# MIMXRT1021 register map
Vendor: nxp.com; File version: 1.0
CPU: CM7 r0p1, little endian, MPU, FPU, VTOR, 4 interrupt priority bits
Registers are 32-bit, read-write, reset 0x0 unless marked. A register's access mark holds for its fields unless they carry their own. Offsets are from the block's base; [hi:lo] are bit positions; {n}, {i} and the like mark numbered series; 'fields as' and 'values as' point back to an identical list.

## IOMUXC (part 3 of 3)
Base 0x401F8000; register names take the prefix IOMUXC_
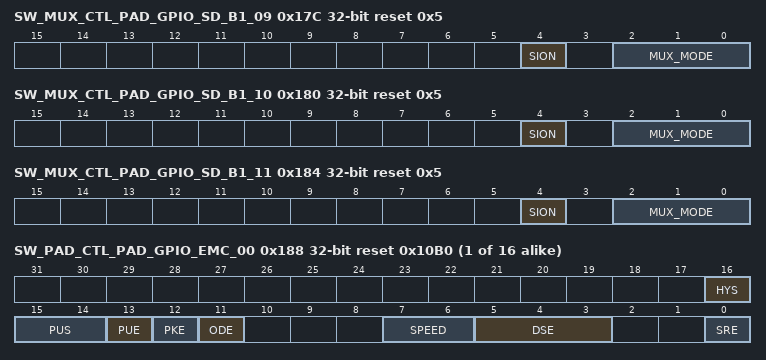
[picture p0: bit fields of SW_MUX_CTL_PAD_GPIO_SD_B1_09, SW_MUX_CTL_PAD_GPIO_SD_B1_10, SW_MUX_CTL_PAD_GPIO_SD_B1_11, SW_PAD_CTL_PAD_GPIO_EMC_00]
0x17C SW_MUX_CTL_PAD_GPIO_SD_B1_09 reset 0x5 — SW_MUX_CTL_PAD_GPIO_SD_B1_09 SW MUX Control Register
  [4] SION — Software Input On Field.
    0=DISABLED (Input Path is determined by functionality); 1=ENABLED (Force input path of pad GPIO_SD_B1_09)
  [2:0] MUX_MODE — MUX Mode Select Field.
    0=ALT0 (Select mux mode: ALT0 mux port: USDHC2_DATA5 of instance: usdhc2); 1=ALT1 (Select mux mode: ALT1 mux port: FLEXSPI_A_DATA02 of instance: flexspi_bus2bit); 2=ALT2 (Select mux mode: ALT2 mux port: ENET_TX_EN of instance: enet); 3=ALT3 (Select mux mode: ALT3 mux port: SAI3_RX_BCLK of instance: sai3); 4=ALT4 (Select mux mode: ALT4 mux port: LPSPI2_SDI of instance: lpspi2); 5=ALT5 (Select mux mode: ALT5 mux port: GPIO3_IO29 of instance: gpio3)
0x180 SW_MUX_CTL_PAD_GPIO_SD_B1_10 reset 0x5 — SW_MUX_CTL_PAD_GPIO_SD_B1_10 SW MUX Control Register
  [4] SION — Software Input On Field.
    0=DISABLED (Input Path is determined by functionality); 1=ENABLED (Force input path of pad GPIO_SD_B1_10)
  [2:0] MUX_MODE — MUX Mode Select Field.
    0=ALT0 (Select mux mode: ALT0 mux port: USDHC2_DATA6 of instance: usdhc2); 1=ALT1 (Select mux mode: ALT1 mux port: FLEXSPI_A_DATA01 of instance: flexspi_bus2bit); 2=ALT2 (Select mux mode: ALT2 mux port: ENET_TDATA00 of instance: enet); 3=ALT3 (Select mux mode: ALT3 mux port: SAI3_RX_SYNC of instance: sai3); 4=ALT4 (Select mux mode: ALT4 mux port: LPSPI2_PCS2 of instance: lpspi2); 5=ALT5 (Select mux mode: ALT5 mux port: GPIO3_IO30 of instance: gpio3)
0x184 SW_MUX_CTL_PAD_GPIO_SD_B1_11 reset 0x5 — SW_MUX_CTL_PAD_GPIO_SD_B1_11 SW MUX Control Register
  [4] SION — Software Input On Field.
    0=DISABLED (Input Path is determined by functionality); 1=ENABLED (Force input path of pad GPIO_SD_B1_11)
  [2:0] MUX_MODE — MUX Mode Select Field.
    0=ALT0 (Select mux mode: ALT0 mux port: USDHC2_DATA7 of instance: usdhc2); 1=ALT1 (Select mux mode: ALT1 mux port: FLEXSPI_A_SS0_B of instance: flexspi_bus2bit); 2=ALT2 (Select mux mode: ALT2 mux port: ENET_TDATA01 of instance: enet); 3=ALT3 (Select mux mode: ALT3 mux port: SAI3_RX_DATA of instance: sai3); 4=ALT4 (Select mux mode: ALT4 mux port: LPSPI2_PCS3 of instance: lpspi2); 5=ALT5 (Select mux mode: ALT5 mux port: GPIO3_IO31 of instance: gpio3)
{0x188+4i} SW_PAD_CTL_PAD_GPIO_EMC_{i:02} reset 0x10B0 (i=0..15) — SW_PAD_CTL_PAD_GPIO_EMC_{i:02} SW PAD Control Register
  [16] HYS — Hyst. Enable Field
    0=HYS_0_Hysteresis_Disabled (Hysteresis Disabled); 1=HYS_1_Hysteresis_Enabled (Hysteresis Enabled)
  [15:14] PUS — Pull Up / Down Config. Field
    0=PUS_0_100K_Ohm_Pull_Down (100K Ohm Pull Down); 1=PUS_1_47K_Ohm_Pull_Up (47K Ohm Pull Up); 2=PUS_2_100K_Ohm_Pull_Up (100K Ohm Pull Up); 3=PUS_3_22K_Ohm_Pull_Up (22K Ohm Pull Up)
  [13] PUE — Pull / Keep Select Field
    0=PUE_0_Keeper (Keeper); 1=PUE_1_Pull (Pull)
  [12] PKE — Pull / Keep Enable Field
    0=PKE_0_Pull_Keeper_Disabled (Pull/Keeper Disabled); 1=PKE_1_Pull_Keeper_Enabled (Pull/Keeper Enabled)
  [11] ODE — Open Drain Enable Field
    0=ODE_0_Open_Drain_Disabled (Open Drain Disabled); 1=ODE_1_Open_Drain_Enabled (Open Drain Enabled)
  [7:6] SPEED
    0=SPEED_0_Low (50MHz); 1=SPEED_1_Medium (100MHz - 150MHz); 2=SPEED_2_Medium (100MHz - 150MHz); 3=SPEED_3_Maximum (150MHz - 200MHz)
  [5:3] DSE — Drive Strength Field
    0=DSE_0_output_driver_disabled_ (output driver disabled;); 1=DSE_1_R0_150_Ohm___3_3V__260_Ohm_1_8V (R0(150 Ohm @ 3.3V, 260 Ohm@1.8V)); {v}=DSE_{v}_R0_{v} (R0/{v}) (v=2..7)
  [0] SRE — Slew Rate Field
    0=SRE_0_Slow_Slew_Rate (Slow Slew Rate); 1=SRE_1_Fast_Slew_Rate (Fast Slew Rate)
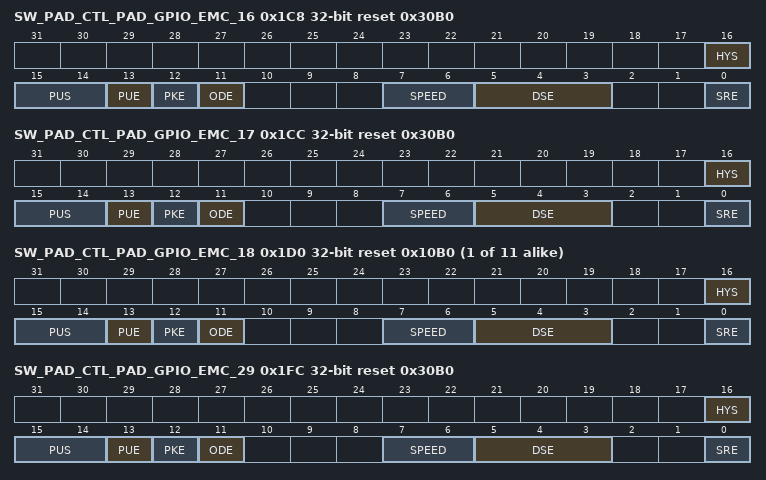
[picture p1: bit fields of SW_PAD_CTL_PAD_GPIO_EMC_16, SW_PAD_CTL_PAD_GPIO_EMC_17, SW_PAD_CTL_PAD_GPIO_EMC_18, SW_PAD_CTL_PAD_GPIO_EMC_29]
0x1C8 SW_PAD_CTL_PAD_GPIO_EMC_16 reset 0x30B0 — SW_PAD_CTL_PAD_GPIO_EMC_16 SW PAD Control Register
  fields as SW_PAD_CTL_PAD_GPIO_EMC_00
0x1CC SW_PAD_CTL_PAD_GPIO_EMC_17 reset 0x30B0 — SW_PAD_CTL_PAD_GPIO_EMC_17 SW PAD Control Register
  fields as SW_PAD_CTL_PAD_GPIO_EMC_00
{0x188+4i} SW_PAD_CTL_PAD_GPIO_EMC_{i} reset 0x10B0 (i=18..28) — SW_PAD_CTL_PAD_GPIO_EMC_{i} SW PAD Control Register
  fields as SW_PAD_CTL_PAD_GPIO_EMC_00
0x1FC SW_PAD_CTL_PAD_GPIO_EMC_29 reset 0x30B0 — SW_PAD_CTL_PAD_GPIO_EMC_29 SW PAD Control Register
  fields as SW_PAD_CTL_PAD_GPIO_EMC_00
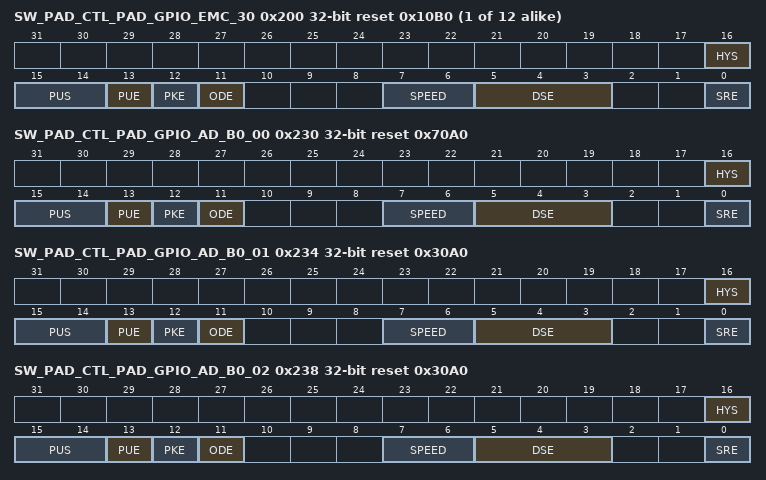
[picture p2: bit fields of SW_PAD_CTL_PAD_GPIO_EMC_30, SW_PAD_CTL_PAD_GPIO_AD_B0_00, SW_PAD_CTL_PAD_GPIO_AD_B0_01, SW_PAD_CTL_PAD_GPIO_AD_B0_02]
{0x188+4i} SW_PAD_CTL_PAD_GPIO_EMC_{i} reset 0x10B0 (i=30..41) — SW_PAD_CTL_PAD_GPIO_EMC_{i} SW PAD Control Register
  fields as SW_PAD_CTL_PAD_GPIO_EMC_00
0x230 SW_PAD_CTL_PAD_GPIO_AD_B0_00 reset 0x70A0 — SW_PAD_CTL_PAD_GPIO_AD_B0_00 SW PAD Control Register
  fields as SW_PAD_CTL_PAD_GPIO_EMC_00
0x234 SW_PAD_CTL_PAD_GPIO_AD_B0_01 reset 0x30A0 — SW_PAD_CTL_PAD_GPIO_AD_B0_01 SW PAD Control Register
  fields as SW_PAD_CTL_PAD_GPIO_EMC_00
0x238 SW_PAD_CTL_PAD_GPIO_AD_B0_02 reset 0x30A0 — SW_PAD_CTL_PAD_GPIO_AD_B0_02 SW PAD Control Register
  fields as SW_PAD_CTL_PAD_GPIO_EMC_00
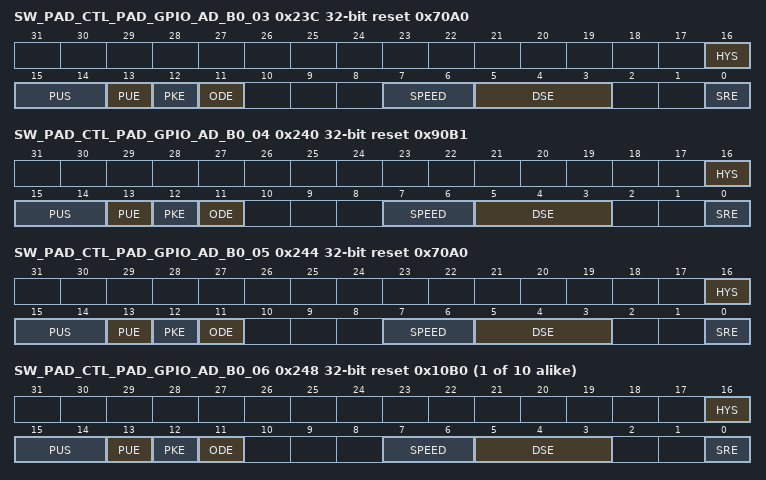
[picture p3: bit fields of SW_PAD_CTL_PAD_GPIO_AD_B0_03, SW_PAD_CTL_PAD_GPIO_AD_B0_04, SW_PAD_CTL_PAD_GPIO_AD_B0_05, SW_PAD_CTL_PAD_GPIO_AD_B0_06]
0x23C SW_PAD_CTL_PAD_GPIO_AD_B0_03 reset 0x70A0 — SW_PAD_CTL_PAD_GPIO_AD_B0_03 SW PAD Control Register
  fields as SW_PAD_CTL_PAD_GPIO_EMC_00
0x240 SW_PAD_CTL_PAD_GPIO_AD_B0_04 reset 0x90B1 — SW_PAD_CTL_PAD_GPIO_AD_B0_04 SW PAD Control Register
  fields as SW_PAD_CTL_PAD_GPIO_EMC_00
0x244 SW_PAD_CTL_PAD_GPIO_AD_B0_05 reset 0x70A0 — SW_PAD_CTL_PAD_GPIO_AD_B0_05 SW PAD Control Register
  fields as SW_PAD_CTL_PAD_GPIO_EMC_00
{0x230+4i} SW_PAD_CTL_PAD_GPIO_AD_B0_{i:02} reset 0x10B0 (i=6..15) — SW_PAD_CTL_PAD_GPIO_AD_B0_{i:02} SW PAD Control Register
  fields as SW_PAD_CTL_PAD_GPIO_EMC_00
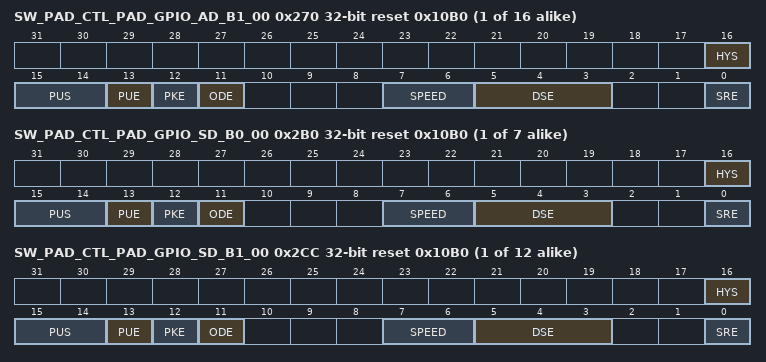
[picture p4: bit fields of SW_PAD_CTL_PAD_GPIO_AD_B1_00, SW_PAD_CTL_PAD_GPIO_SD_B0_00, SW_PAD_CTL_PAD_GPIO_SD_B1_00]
{0x270+4i} SW_PAD_CTL_PAD_GPIO_AD_B1_{i:02} reset 0x10B0 (i=0..15) — SW_PAD_CTL_PAD_GPIO_AD_B1_{i:02} SW PAD Control Register
  fields as SW_PAD_CTL_PAD_GPIO_EMC_00
{0x2B0+4i} SW_PAD_CTL_PAD_GPIO_SD_B0_{i:02} reset 0x10B0 (i=0..6) — SW_PAD_CTL_PAD_GPIO_SD_B0_{i:02} SW PAD Control Register
  fields as SW_PAD_CTL_PAD_GPIO_EMC_00
{0x2CC+4i} SW_PAD_CTL_PAD_GPIO_SD_B1_{i:02} reset 0x10B0 (i=0..11) — SW_PAD_CTL_PAD_GPIO_SD_B1_{i:02} SW PAD Control Register
  fields as SW_PAD_CTL_PAD_GPIO_EMC_00
0x2FC ANATOP_USB_OTG_ID_SELECT_INPUT — ANATOP_USB_OTG_ID_SELECT_INPUT DAISY Register
  [1:0] DAISY — Selecting Pads Involved in Daisy Chain.
    0=GPIO_AD_B0_05_ALT6 (Selecting Pad: GPIO_AD_B0_05 for Mode: ALT6); 1=GPIO_AD_B1_11_ALT0 (Selecting Pad: GPIO_AD_B1_11 for Mode: ALT0); 2=GPIO_EMC_40_ALT3 (Selecting Pad: GPIO_EMC_40 for Mode: ALT3)
0x300 CCM_PMIC_READY_SELECT_INPUT — CCM_PMIC_READY_SELECT_INPUT DAISY Register
  [1:0] DAISY — Selecting Pads Involved in Daisy Chain.
    0=GPIO_EMC_13_ALT7 (Selecting Pad: GPIO_EMC_13 for Mode: ALT7); 1=GPIO_SD_B1_05_ALT6 (Selecting Pad: GPIO_SD_B1_05 for Mode: ALT6); 2=GPIO_AD_B0_03_ALT7 (Selecting Pad: GPIO_AD_B0_03 for Mode: ALT7); 3=GPIO_EMC_36_ALT3 (Selecting Pad: GPIO_EMC_36 for Mode: ALT3)
0x304 ENET_RMII_SELECT_INPUT — ENET_RMII_SELECT_INPUT DAISY Register
  [0] DAISY — Selecting Pads Involved in Daisy Chain.
    0=GPIO_SD_B1_04_ALT3 (Selecting Pad: GPIO_SD_B1_04 for Mode: ALT3); 1=GPIO_AD_B0_08_ALT4 (Selecting Pad: GPIO_AD_B0_08 for Mode: ALT4)
0x308 ENET_MDIO_SELECT_INPUT — ENET_MDIO_SELECT_INPUT DAISY Register
  [1:0] DAISY — Selecting Pads Involved in Daisy Chain.
    0=GPIO_SD_B0_02_ALT6 (Selecting Pad: GPIO_SD_B0_02 for Mode: ALT6); 1=GPIO_AD_B0_04_ALT4 (Selecting Pad: GPIO_AD_B0_04 for Mode: ALT4); 2=GPIO_EMC_40_ALT4 (Selecting Pad: GPIO_EMC_40 for Mode: ALT4)
0x30C ENET_RX_DATA0_SELECT_INPUT — ENET_RX_DATA0_SELECT_INPUT DAISY Register
  [0] DAISY — Selecting Pads Involved in Daisy Chain.
    0=GPIO_SD_B1_06_ALT2 (Selecting Pad: GPIO_SD_B1_06 for Mode: ALT2); 1=GPIO_AD_B0_10_ALT0 (Selecting Pad: GPIO_AD_B0_10 for Mode: ALT0)
0x310 ENET_RX_DATA1_SELECT_INPUT — ENET_RX_DATA1_SELECT_INPUT DAISY Register
  [0] DAISY — Selecting Pads Involved in Daisy Chain.
    0=GPIO_SD_B1_05_ALT2 (Selecting Pad: GPIO_SD_B1_05 for Mode: ALT2); 1=GPIO_AD_B0_09_ALT0 (Selecting Pad: GPIO_AD_B0_09 for Mode: ALT0)
0x314 ENET_RX_EN_SELECT_INPUT — ENET_RX_EN_SELECT_INPUT DAISY Register
  [0] DAISY — Selecting Pads Involved in Daisy Chain.
    0=GPIO_SD_B1_07_ALT2 (Selecting Pad: GPIO_SD_B1_07 for Mode: ALT2); 1=GPIO_AD_B0_11_ALT0 (Selecting Pad: GPIO_AD_B0_11 for Mode: ALT0)
0x318 ENET_RX_ERR_SELECT_INPUT — ENET_RX_ERR_SELECT_INPUT DAISY Register
  [0] DAISY — Selecting Pads Involved in Daisy Chain.
    0=GPIO_SD_B1_08_ALT2 (Selecting Pad: GPIO_SD_B1_08 for Mode: ALT2); 1=GPIO_AD_B0_12_ALT0 (Selecting Pad: GPIO_AD_B0_12 for Mode: ALT0)
0x31C ENET_TX_CLK_SELECT_INPUT — ENET_TX_CLK_SELECT_INPUT DAISY Register
  [0] DAISY — Selecting Pads Involved in Daisy Chain.
    0=GPIO_SD_B1_04_ALT2 (Selecting Pad: GPIO_SD_B1_04 for Mode: ALT2); 1=GPIO_AD_B0_08_ALT0 (Selecting Pad: GPIO_AD_B0_08 for Mode: ALT0)
0x320 FLEXCAN1_RX_SELECT_INPUT — FLEXCAN1_RX_SELECT_INPUT DAISY Register
  [1:0] DAISY — Selecting Pads Involved in Daisy Chain.
    0=GPIO_EMC_01_ALT6 (Selecting Pad: GPIO_EMC_01 for Mode: ALT6); 1=GPIO_SD_B1_01_ALT4 (Selecting Pad: GPIO_SD_B1_01 for Mode: ALT4); 2=GPIO_AD_B0_05_ALT1 (Selecting Pad: GPIO_AD_B0_05 for Mode: ALT1); 3=GPIO_EMC_15_ALT6 (Selecting Pad: GPIO_EMC_15 for Mode: ALT6)
0x324 FLEXCAN2_RX_SELECT_INPUT — FLEXCAN2_RX_SELECT_INPUT DAISY Register
  [1:0] DAISY — Selecting Pads Involved in Daisy Chain.
    0=GPIO_SD_B0_05_ALT1 (Selecting Pad: GPIO_SD_B0_05 for Mode: ALT1); 1=GPIO_EMC_09_ALT2 (Selecting Pad: GPIO_EMC_09 for Mode: ALT2); 2=GPIO_AD_B0_15_ALT1 (Selecting Pad: GPIO_AD_B0_15 for Mode: ALT1); 3=GPIO_AD_B1_01_ALT2 (Selecting Pad: GPIO_AD_B1_01 for Mode: ALT2)
0x328 FLEXPWM1_PWMA0_SELECT_INPUT — FLEXPWM1_PWMA0_SELECT_INPUT DAISY Register
  [0] DAISY — Selecting Pads Involved in Daisy Chain.
    0=GPIO_AD_B1_06_ALT1 (Selecting Pad: GPIO_AD_B1_06 for Mode: ALT1); 1=GPIO_EMC_26_ALT1 (Selecting Pad: GPIO_EMC_26 for Mode: ALT1)
0x32C FLEXPWM1_PWMA1_SELECT_INPUT — FLEXPWM1_PWMA1_SELECT_INPUT DAISY Register
  [0] DAISY — Selecting Pads Involved in Daisy Chain.
    0=GPIO_AD_B1_08_ALT1 (Selecting Pad: GPIO_AD_B1_08 for Mode: ALT1); 1=GPIO_EMC_24_ALT1 (Selecting Pad: GPIO_EMC_24 for Mode: ALT1)
0x330 FLEXPWM1_PWMA2_SELECT_INPUT — FLEXPWM1_PWMA2_SELECT_INPUT DAISY Register
  [0] DAISY — Selecting Pads Involved in Daisy Chain.
    0=GPIO_AD_B1_10_ALT1 (Selecting Pad: GPIO_AD_B1_10 for Mode: ALT1); 1=GPIO_EMC_22_ALT1 (Selecting Pad: GPIO_EMC_22 for Mode: ALT1)
0x334 FLEXPWM1_PWMA3_SELECT_INPUT — FLEXPWM1_PWMA3_SELECT_INPUT DAISY Register
  [0] DAISY — Selecting Pads Involved in Daisy Chain.
    0=GPIO_AD_B1_12_ALT6 (Selecting Pad: GPIO_AD_B1_12 for Mode: ALT6); 1=GPIO_EMC_20_ALT1 (Selecting Pad: GPIO_EMC_20 for Mode: ALT1)
0x338 FLEXPWM1_PWMB0_SELECT_INPUT — FLEXPWM1_PWMB0_SELECT_INPUT DAISY Register
  [0] DAISY — Selecting Pads Involved in Daisy Chain.
    0=GPIO_AD_B1_07_ALT1 (Selecting Pad: GPIO_AD_B1_07 for Mode: ALT1); 1=GPIO_EMC_27_ALT1 (Selecting Pad: GPIO_EMC_27 for Mode: ALT1)
0x33C FLEXPWM1_PWMB1_SELECT_INPUT — FLEXPWM1_PWMB1_SELECT_INPUT DAISY Register
  [0] DAISY — Selecting Pads Involved in Daisy Chain.
    0=GPIO_AD_B1_09_ALT1 (Selecting Pad: GPIO_AD_B1_09 for Mode: ALT1); 1=GPIO_EMC_25_ALT1 (Selecting Pad: GPIO_EMC_25 for Mode: ALT1)
0x340 FLEXPWM1_PWMB2_SELECT_INPUT — FLEXPWM1_PWMB2_SELECT_INPUT DAISY Register
  [0] DAISY — Selecting Pads Involved in Daisy Chain.
    0=GPIO_AD_B1_11_ALT1 (Selecting Pad: GPIO_AD_B1_11 for Mode: ALT1); 1=GPIO_EMC_23_ALT1 (Selecting Pad: GPIO_EMC_23 for Mode: ALT1)
0x344 FLEXPWM1_PWMB3_SELECT_INPUT — FLEXPWM1_PWMB3_SELECT_INPUT DAISY Register
  [0] DAISY — Selecting Pads Involved in Daisy Chain.
    0=GPIO_AD_B1_13_ALT6 (Selecting Pad: GPIO_AD_B1_13 for Mode: ALT6); 1=GPIO_EMC_21_ALT1 (Selecting Pad: GPIO_EMC_21 for Mode: ALT1)
0x348 FLEXPWM2_PWMA0_SELECT_INPUT — FLEXPWM2_PWMA0_SELECT_INPUT DAISY Register
  [0] DAISY — Selecting Pads Involved in Daisy Chain.
    0=GPIO_AD_B0_14_ALT4 (Selecting Pad: GPIO_AD_B0_14 for Mode: ALT4); 1=GPIO_EMC_38_ALT1 (Selecting Pad: GPIO_EMC_38 for Mode: ALT1)
0x34C FLEXPWM2_PWMA1_SELECT_INPUT — FLEXPWM2_PWMA1_SELECT_INPUT DAISY Register
  [0] DAISY — Selecting Pads Involved in Daisy Chain.
    0=GPIO_AD_B0_12_ALT4 (Selecting Pad: GPIO_AD_B0_12 for Mode: ALT4); 1=GPIO_EMC_36_ALT1 (Selecting Pad: GPIO_EMC_36 for Mode: ALT1)
0x350 FLEXPWM2_PWMA2_SELECT_INPUT — FLEXPWM2_PWMA2_SELECT_INPUT DAISY Register
  [0] DAISY — Selecting Pads Involved in Daisy Chain.
    0=GPIO_AD_B0_10_ALT4 (Selecting Pad: GPIO_AD_B0_10 for Mode: ALT4); 1=GPIO_EMC_30_ALT1 (Selecting Pad: GPIO_EMC_30 for Mode: ALT1)
0x354 FLEXPWM2_PWMA3_SELECT_INPUT — FLEXPWM2_PWMA3_SELECT_INPUT DAISY Register
  [0] DAISY — Selecting Pads Involved in Daisy Chain.
    0=GPIO_AD_B0_06_ALT4 (Selecting Pad: GPIO_AD_B0_06 for Mode: ALT4); 1=GPIO_EMC_28_ALT1 (Selecting Pad: GPIO_EMC_28 for Mode: ALT1)
0x358 FLEXPWM2_PWMB0_SELECT_INPUT — FLEXPWM2_PWMB0_SELECT_INPUT DAISY Register
  [0] DAISY — Selecting Pads Involved in Daisy Chain.
    0=GPIO_AD_B0_15_ALT4 (Selecting Pad: GPIO_AD_B0_15 for Mode: ALT4); 1=GPIO_EMC_39_ALT1 (Selecting Pad: GPIO_EMC_39 for Mode: ALT1)
0x35C FLEXPWM2_PWMB1_SELECT_INPUT — FLEXPWM2_PWMB1_SELECT_INPUT DAISY Register
  [0] DAISY — Selecting Pads Involved in Daisy Chain.
    0=GPIO_AD_B0_13_ALT4 (Selecting Pad: GPIO_AD_B0_13 for Mode: ALT4); 1=GPIO_EMC_37_ALT1 (Selecting Pad: GPIO_EMC_37 for Mode: ALT1)
0x360 FLEXPWM2_PWMB2_SELECT_INPUT — FLEXPWM2_PWMB2_SELECT_INPUT DAISY Register
  [0] DAISY — Selecting Pads Involved in Daisy Chain.
    0=GPIO_AD_B0_11_ALT4 (Selecting Pad: GPIO_AD_B0_11 for Mode: ALT4); 1=GPIO_EMC_31_ALT1 (Selecting Pad: GPIO_EMC_31 for Mode: ALT1)
0x364 FLEXPWM2_PWMB3_SELECT_INPUT — FLEXPWM2_PWMB3_SELECT_INPUT DAISY Register
  [0] DAISY — Selecting Pads Involved in Daisy Chain.
    0=GPIO_AD_B0_07_ALT4 (Selecting Pad: GPIO_AD_B0_07 for Mode: ALT4); 1=GPIO_EMC_29_ALT1 (Selecting Pad: GPIO_EMC_29 for Mode: ALT1)
0x368 FLEXSPI_A_DATA0_SELECT_INPUT — FLEXSPI_A_DATA0_SELECT_INPUT DAISY Register
  [0] DAISY — Selecting Pads Involved in Daisy Chain.
    0=GPIO_SD_B1_08_ALT1 (Selecting Pad: GPIO_SD_B1_08 for Mode: ALT1); 1=GPIO_AD_B1_02_ALT1 (Selecting Pad: GPIO_AD_B1_02 for Mode: ALT1)
0x36C FLEXSPI_A_DATA1_SELECT_INPUT — FLEXSPI_A_DATA1_SELECT_INPUT DAISY Register
  [0] DAISY — Selecting Pads Involved in Daisy Chain.
    0=GPIO_SD_B1_10_ALT1 (Selecting Pad: GPIO_SD_B1_10 for Mode: ALT1); 1=GPIO_AD_B1_04_ALT1 (Selecting Pad: GPIO_AD_B1_04 for Mode: ALT1)
0x370 FLEXSPI_A_DATA2_SELECT_INPUT — FLEXSPI_A_DATA2_SELECT_INPUT DAISY Register
  [0] DAISY — Selecting Pads Involved in Daisy Chain.
    0=GPIO_SD_B1_09_ALT1 (Selecting Pad: GPIO_SD_B1_09 for Mode: ALT1); 1=GPIO_AD_B1_03_ALT1 (Selecting Pad: GPIO_AD_B1_03 for Mode: ALT1)
0x374 FLEXSPI_A_DATA3_SELECT_INPUT — FLEXSPI_A_DATA3_SELECT_INPUT DAISY Register
  [0] DAISY — Selecting Pads Involved in Daisy Chain.
    0=GPIO_SD_B1_06_ALT1 (Selecting Pad: GPIO_SD_B1_06 for Mode: ALT1); 1=GPIO_AD_B1_00_ALT1 (Selecting Pad: GPIO_AD_B1_00 for Mode: ALT1)
0x378 FLEXSPI_A_SCLK_SELECT_INPUT — FLEXSPI_A_SCLK_SELECT_INPUT DAISY Register
  [0] DAISY — Selecting Pads Involved in Daisy Chain.
    0=GPIO_SD_B1_07_ALT1 (Selecting Pad: GPIO_SD_B1_07 for Mode: ALT1); 1=GPIO_AD_B1_01_ALT1 (Selecting Pad: GPIO_AD_B1_01 for Mode: ALT1)
0x37C LPI2C1_SCL_SELECT_INPUT — LPI2C1_SCL_SELECT_INPUT DAISY Register
  [0] DAISY — Selecting Pads Involved in Daisy Chain.
    0=GPIO_EMC_02_ALT6 (Selecting Pad: GPIO_EMC_02 for Mode: ALT6); 1=GPIO_AD_B1_14_ALT0 (Selecting Pad: GPIO_AD_B1_14 for Mode: ALT0)
0x380 LPI2C1_SDA_SELECT_INPUT — LPI2C1_SDA_SELECT_INPUT DAISY Register
  [0] DAISY — Selecting Pads Involved in Daisy Chain.
    0=GPIO_EMC_03_ALT6 (Selecting Pad: GPIO_EMC_03 for Mode: ALT6); 1=GPIO_AD_B1_15_ALT0 (Selecting Pad: GPIO_AD_B1_15 for Mode: ALT0)
0x384 LPI2C2_SCL_SELECT_INPUT — LPI2C2_SCL_SELECT_INPUT DAISY Register
  [0] DAISY — Selecting Pads Involved in Daisy Chain.
    0=GPIO_AD_B1_08_ALT0 (Selecting Pad: GPIO_AD_B1_08 for Mode: ALT0); 1=GPIO_EMC_19_ALT2 (Selecting Pad: GPIO_EMC_19 for Mode: ALT2)
0x388 LPI2C2_SDA_SELECT_INPUT — LPI2C2_SDA_SELECT_INPUT DAISY Register
  [0] DAISY — Selecting Pads Involved in Daisy Chain.
    0=GPIO_AD_B1_09_ALT0 (Selecting Pad: GPIO_AD_B1_09 for Mode: ALT0); 1=GPIO_EMC_18_ALT2 (Selecting Pad: GPIO_EMC_18 for Mode: ALT2)
0x38C LPI2C3_SCL_SELECT_INPUT — LPI2C3_SCL_SELECT_INPUT DAISY Register
  [0] DAISY — Selecting Pads Involved in Daisy Chain.
    0=GPIO_SD_B0_00_ALT4 (Selecting Pad: GPIO_SD_B0_00 for Mode: ALT4); 1=GPIO_AD_B0_08_ALT1 (Selecting Pad: GPIO_AD_B0_08 for Mode: ALT1)
0x390 LPI2C3_SDA_SELECT_INPUT — LPI2C3_SDA_SELECT_INPUT DAISY Register
  [0] DAISY — Selecting Pads Involved in Daisy Chain.
    0=GPIO_SD_B0_01_ALT4 (Selecting Pad: GPIO_SD_B0_01 for Mode: ALT4); 1=GPIO_AD_B0_09_ALT1 (Selecting Pad: GPIO_AD_B0_09 for Mode: ALT1)
0x394 LPI2C4_SCL_SELECT_INPUT — LPI2C4_SCL_SELECT_INPUT DAISY Register
  [0] DAISY — Selecting Pads Involved in Daisy Chain.
    0=GPIO_EMC_11_ALT2 (Selecting Pad: GPIO_EMC_11 for Mode: ALT2); 1=GPIO_SD_B1_02_ALT3 (Selecting Pad: GPIO_SD_B1_02 for Mode: ALT3)
0x398 LPI2C4_SDA_SELECT_INPUT — LPI2C4_SDA_SELECT_INPUT DAISY Register
  [0] DAISY — Selecting Pads Involved in Daisy Chain.
    0=GPIO_EMC_10_ALT2 (Selecting Pad: GPIO_EMC_10 for Mode: ALT2); 1=GPIO_SD_B1_03_ALT3 (Selecting Pad: GPIO_SD_B1_03 for Mode: ALT3)
0x39C LPSPI1_PCS0_SELECT_INPUT — LPSPI1_PCS0_SELECT_INPUT DAISY Register
  [0] DAISY — Selecting Pads Involved in Daisy Chain.
    0=GPIO_SD_B0_03_ALT4 (Selecting Pad: GPIO_SD_B0_03 for Mode: ALT4); 1=GPIO_AD_B0_11_ALT1 (Selecting Pad: GPIO_AD_B0_11 for Mode: ALT1)
0x3A0 LPSPI1_SCK_SELECT_INPUT — LPSPI1_SCK_SELECT_INPUT DAISY Register
  [0] DAISY — Selecting Pads Involved in Daisy Chain.
    0=GPIO_SD_B0_02_ALT4 (Selecting Pad: GPIO_SD_B0_02 for Mode: ALT4); 1=GPIO_AD_B0_10_ALT1 (Selecting Pad: GPIO_AD_B0_10 for Mode: ALT1)
0x3A4 LPSPI1_SDI_SELECT_INPUT — LPSPI1_SDI_SELECT_INPUT DAISY Register
  [0] DAISY — Selecting Pads Involved in Daisy Chain.
    0=GPIO_SD_B0_05_ALT4 (Selecting Pad: GPIO_SD_B0_05 for Mode: ALT4); 1=GPIO_AD_B0_13_ALT1 (Selecting Pad: GPIO_AD_B0_13 for Mode: ALT1)
0x3A8 LPSPI1_SDO_SELECT_INPUT — LPSPI1_SDO_SELECT_INPUT DAISY Register
  [0] DAISY — Selecting Pads Involved in Daisy Chain.
    0=GPIO_SD_B0_04_ALT4 (Selecting Pad: GPIO_SD_B0_04 for Mode: ALT4); 1=GPIO_AD_B0_12_ALT1 (Selecting Pad: GPIO_AD_B0_12 for Mode: ALT1)
0x3AC LPSPI2_PCS0_SELECT_INPUT — LPSPI2_PCS0_SELECT_INPUT DAISY Register
  [1:0] DAISY — Selecting Pads Involved in Daisy Chain.
    0=GPIO_EMC_01_ALT4 (Selecting Pad: GPIO_EMC_01 for Mode: ALT4); 1=GPIO_EMC_11_ALT4 (Selecting Pad: GPIO_EMC_11 for Mode: ALT4); 2=GPIO_SD_B1_06_ALT4 (Selecting Pad: GPIO_SD_B1_06 for Mode: ALT4)
0x3B0 LPSPI2_SCK_SELECT_INPUT — LPSPI2_SCK_SELECT_INPUT DAISY Register
  [1:0] DAISY — Selecting Pads Involved in Daisy Chain.
    0=_GPIO_EMC_00_ALT4 (Selecting Pad: GPIO_EMC_00 for Mode: ALT4); 1=_GPIO_EMC_10_ALT4 (Selecting Pad: GPIO_EMC_10 for Mode: ALT4); 2=_GPIO_SD_B1_07_ALT4 (Selecting Pad: GPIO_SD_B1_07 for Mode: ALT4)
0x3B4 LPSPI2_SDI_SELECT_INPUT — LPSPI2_SDI_SELECT_INPUT DAISY Register
  [1:0] DAISY — Selecting Pads Involved in Daisy Chain.
    0=GPIO_EMC_03_ALT4 (Selecting Pad: GPIO_EMC_03 for Mode: ALT4); 1=GPIO_EMC_13_ALT4 (Selecting Pad: GPIO_EMC_13 for Mode: ALT4); 2=GPIO_SD_B1_09_ALT4 (Selecting Pad: GPIO_SD_B1_09 for Mode: ALT4)
0x3B8 LPSPI2_SDO_SELECT_INPUT — LPSPI2_SDO_SELECT_INPUT DAISY Register
  [1:0] DAISY — Selecting Pads Involved in Daisy Chain.
    0=GPIO_EMC_02_ALT4 (Selecting Pad: GPIO_EMC_02 for Mode: ALT4); 1=GPIO_EMC_12_ALT4 (Selecting Pad: GPIO_EMC_12 for Mode: ALT4); 2=GPIO_SD_B1_08_ALT4 (Selecting Pad: GPIO_SD_B1_08 for Mode: ALT4)
0x3BC LPSPI4_PCS0_SELECT_INPUT — LPSPI4_PCS0_SELECT_INPUT DAISY Register
  [0] DAISY — Selecting Pads Involved in Daisy Chain.
    0=GPIO_AD_B1_03_ALT2 (Selecting Pad: GPIO_AD_B1_03 for Mode: ALT2); 1=GPIO_EMC_33_ALT4 (Selecting Pad: GPIO_EMC_33 for Mode: ALT4)
0x3C0 LPSPI4_SCK_SELECT_INPUT — LPSPI4_SCK_SELECT_INPUT DAISY Register
  [0] DAISY — Selecting Pads Involved in Daisy Chain.
    0=GPIO_AD_B1_02_ALT2 (Selecting Pad: GPIO_AD_B1_02 for Mode: ALT2); 1=GPIO_EMC_32_ALT4 (Selecting Pad: GPIO_EMC_32 for Mode: ALT4)
0x3C4 LPSPI4_SDI_SELECT_INPUT — LPSPI4_SDI_SELECT_INPUT DAISY Register
  [0] DAISY — Selecting Pads Involved in Daisy Chain.
    0=GPIO_AD_B1_05_ALT2 (Selecting Pad: GPIO_AD_B1_05 for Mode: ALT2); 1=GPIO_EMC_35_ALT4 (Selecting Pad: GPIO_EMC_35 for Mode: ALT4)
0x3C8 LPSPI4_SDO_SELECT_INPUT — LPSPI4_SDO_SELECT_INPUT DAISY Register
  [0] DAISY — Selecting Pads Involved in Daisy Chain.
    0=GPIO_AD_B1_04_ALT2 (Selecting Pad: GPIO_AD_B1_04 for Mode: ALT2); 1=GPIO_EMC_34_ALT4 (Selecting Pad: GPIO_EMC_34 for Mode: ALT4)
0x3CC LPUART2_CTS_B_SELECT_INPUT — LPUART2_CTS_B_SELECT_INPUT DAISY Register
  [0] DAISY — Selecting Pads Involved in Daisy Chain.
    0=GPIO_AD_B1_06_ALT2 (Selecting Pad: GPIO_AD_B1_06 for Mode: ALT2); 1=GPIO_EMC_20_ALT2 (Selecting Pad: GPIO_EMC_20 for Mode: ALT2)
0x3D0 LPUART2_RX_SELECT_INPUT — LPUART2_RX_SELECT_INPUT DAISY Register
  [0] DAISY — Selecting Pads Involved in Daisy Chain.
    0=GPIO_AD_B1_09_ALT2 (Selecting Pad: GPIO_AD_B1_09 for Mode: ALT2); 1=GPIO_EMC_23_ALT2 (Selecting Pad: GPIO_EMC_23 for Mode: ALT2)
0x3D4 LPUART2_TX_SELECT_INPUT — LPUART2_TX_SELECT_INPUT DAISY Register
  [0] DAISY — Selecting Pads Involved in Daisy Chain.
    0=GPIO_AD_B1_08_ALT2 (Selecting Pad: GPIO_AD_B1_08 for Mode: ALT2); 1=GPIO_EMC_22_ALT2 (Selecting Pad: GPIO_EMC_22 for Mode: ALT2)
0x3D8 LPUART3_RX_SELECT_INPUT — LPUART3_RX_SELECT_INPUT DAISY Register
  [0] DAISY — Selecting Pads Involved in Daisy Chain.
    0=GPIO_EMC_07_ALT2 (Selecting Pad: GPIO_EMC_07 for Mode: ALT2); 1=GPIO_AD_B0_15_ALT2 (Selecting Pad: GPIO_AD_B0_15 for Mode: ALT2)
0x3DC LPUART3_TX_SELECT_INPUT — LPUART3_TX_SELECT_INPUT DAISY Register
  [0] DAISY — Selecting Pads Involved in Daisy Chain.
    0=GPIO_EMC_06_ALT2 (Selecting Pad: GPIO_EMC_06 for Mode: ALT2); 1=GPIO_AD_B0_14_ALT2 (Selecting Pad: GPIO_AD_B0_14 for Mode: ALT2)
0x3E0 LPUART4_CTS_B_SELECT_INPUT — LPUART4_CTS_B_SELECT_INPUT DAISY Register
  [0] DAISY — Selecting Pads Involved in Daisy Chain.
    0=GPIO_EMC_00_ALT2 (Selecting Pad: GPIO_EMC_00 for Mode: ALT2); 1=GPIO_EMC_30_ALT2 (Selecting Pad: GPIO_EMC_30 for Mode: ALT2)
0x3E4 LPUART4_RX_SELECT_INPUT — LPUART4_RX_SELECT_INPUT DAISY Register
  [1:0] DAISY — Selecting Pads Involved in Daisy Chain.
    0=GPIO_EMC_03_ALT2 (Selecting Pad: GPIO_EMC_03 for Mode: ALT2); 1=GPIO_AD_B1_11_ALT2 (Selecting Pad: GPIO_AD_B1_11 for Mode: ALT2); 2=GPIO_EMC_33_ALT2 (Selecting Pad: GPIO_EMC_33 for Mode: ALT2)
0x3E8 LPUART4_TX_SELECT_INPUT — LPUART4_TX_SELECT_INPUT DAISY Register
  [1:0] DAISY — Selecting Pads Involved in Daisy Chain.
    0=GPIO_EMC_02_ALT2 (Selecting Pad: GPIO_EMC_02 for Mode: ALT2); 1=GPIO_AD_B1_10_ALT2 (Selecting Pad: GPIO_AD_B1_10 for Mode: ALT2); 2=GPIO_EMC_32_ALT2 (Selecting Pad: GPIO_EMC_32 for Mode: ALT2)
0x3EC LPUART5_RX_SELECT_INPUT — LPUART5_RX_SELECT_INPUT DAISY Register
  [0] DAISY — Selecting Pads Involved in Daisy Chain.
    0=GPIO_AD_B0_11_ALT2 (Selecting Pad: GPIO_AD_B0_11 for Mode: ALT2); 1=GPIO_EMC_39_ALT2 (Selecting Pad: GPIO_EMC_39 for Mode: ALT2)
0x3F0 LPUART5_TX_SELECT_INPUT — LPUART5_TX_SELECT_INPUT DAISY Register
  [0] DAISY — Selecting Pads Involved in Daisy Chain.
    0=GPIO_AD_B0_10_ALT2 (Selecting Pad: GPIO_AD_B0_10 for Mode: ALT2); 1=GPIO_EMC_38_ALT2 (Selecting Pad: GPIO_EMC_38 for Mode: ALT2)
0x3F4 LPUART6_RX_SELECT_INPUT — LPUART6_RX_SELECT_INPUT DAISY Register
  [0] DAISY — Selecting Pads Involved in Daisy Chain.
    0=GPIO_EMC_13_ALT2 (Selecting Pad: GPIO_EMC_13 for Mode: ALT2); 1=GPIO_SD_B1_01_ALT2 (Selecting Pad: GPIO_SD_B1_01 for Mode: ALT2)
0x3F8 LPUART6_TX_SELECT_INPUT — LPUART6_TX_SELECT_INPUT DAISY Register
  [0] DAISY — Selecting Pads Involved in Daisy Chain.
    0=GPIO_EMC_12_ALT2 (Selecting Pad: GPIO_EMC_12 for Mode: ALT2); 1=GPIO_SD_B1_00_ALT2 (Selecting Pad: GPIO_SD_B1_00 for Mode: ALT2)
0x3FC LPUART7_RX_SELECT_INPUT — LPUART7_RX_SELECT_INPUT DAISY Register
  [0] DAISY — Selecting Pads Involved in Daisy Chain.
    0=GPIO_SD_B0_05_ALT2 (Selecting Pad: GPIO_SD_B0_05 for Mode: ALT2); 1=GPIO_EMC_35_ALT2 (Selecting Pad: GPIO_EMC_35 for Mode: ALT2)
0x400 LPUART7_TX_SELECT_INPUT — LPUART7_TX_SELECT_INPUT DAISY Register
  [0] DAISY — Selecting Pads Involved in Daisy Chain.
    0=GPIO_SD_B0_04_ALT2 (Selecting Pad: GPIO_SD_B0_04 for Mode: ALT2); 1=GPIO_EMC_34_ALT2 (Selecting Pad: GPIO_EMC_34 for Mode: ALT2)
0x404 LPUART8_RX_SELECT_INPUT — LPUART8_RX_SELECT_INPUT DAISY Register
  [0] DAISY — Selecting Pads Involved in Daisy Chain.
    0=GPIO_SD_B1_03_ALT2 (Selecting Pad: GPIO_SD_B1_03 for Mode: ALT2); 1=GPIO_EMC_27_ALT2 (Selecting Pad: GPIO_EMC_27 for Mode: ALT2)
0x408 LPUART8_TX_SELECT_INPUT — LPUART8_TX_SELECT_INPUT DAISY Register
  [0] DAISY — Selecting Pads Involved in Daisy Chain.
    0=GPIO_SD_B1_02_ALT2 (Selecting Pad: GPIO_SD_B1_02 for Mode: ALT2); 1=GPIO_EMC_26_ALT2 (Selecting Pad: GPIO_EMC_26 for Mode: ALT2)
0x40C NMI_SELECT_INPUT — NMI_SELECT_INPUT DAISY Register
  [0] DAISY — Selecting Pads Involved in Daisy Chain.
    0=GPIO_AD_B0_05_ALT7 (Selecting Pad: GPIO_AD_B0_05 for Mode: ALT7); 1=WAKEUP_ALT7 (Selecting Pad: WAKEUP for Mode: ALT7)
{0x410+4i} QTIMER1_TIMER{i}_INPUT_SELECT_INPUT (i=0..3) — QTIMER1_TIMER{i}_INPUT_SELECT_INPUT DAISY Register
  [0] DAISY — Selecting Pads Involved in Daisy Chain.
    0=GPIO_SD_B0_{i:02}_ALT1 (Selecting Pad: GPIO_SD_B0_{i:02} for Mode: ALT1); 1=GPIO_EMC_{i+32}_ALT1 (Selecting Pad: GPIO_EMC_{i+32} for Mode: ALT1)
{0x420+4i} QTIMER2_TIMER{i}_INPUT_SELECT_INPUT (i=0..3) — QTIMER2_TIMER{i}_INPUT_SELECT_INPUT DAISY Register
  [0] DAISY — Selecting Pads Involved in Daisy Chain.
    0=GPIO_EMC_{i:02}_ALT1 (Selecting Pad: GPIO_EMC_{i:02} for Mode: ALT1); 1=GPIO_AD_B0_{i+4:02}_ALT3 (Selecting Pad: GPIO_AD_B0_{i+4:02} for Mode: ALT3)
0x430 SAI1_MCLK_SELECT_INPUT — SAI1_MCLK_SELECT_INPUT DAISY Register
  [1:0] DAISY — Selecting Pads Involved in Daisy Chain.
    0=GPIO_SD_B0_00_ALT2 (Selecting Pad: GPIO_SD_B0_00 for Mode: ALT2); 1=GPIO_AD_B0_03_ALT3 (Selecting Pad: GPIO_AD_B0_03 for Mode: ALT3); 2=GPIO_AD_B1_00_ALT3 (Selecting Pad: GPIO_AD_B1_00 for Mode: ALT3); 3=GPIO_EMC_20_ALT3 (Selecting Pad: GPIO_EMC_20 for Mode: ALT3)
0x434 SAI1_RX_BCLK_SELECT_INPUT — SAI1_RX_BCLK_SELECT_INPUT DAISY Register
  [1:0] DAISY — Selecting Pads Involved in Daisy Chain.
    0=GPIO_AD_B1_06_ALT3 (Selecting Pad: GPIO_AD_B1_06 for Mode: ALT3); 1=GPIO_EMC_14_ALT3 (Selecting Pad: GPIO_EMC_14 for Mode: ALT3); 2=GPIO_EMC_19_ALT3 (Selecting Pad: GPIO_EMC_19 for Mode: ALT3)
0x438 SAI1_RX_DATA0_SELECT_INPUT — SAI1_RX_DATA0_SELECT_INPUT DAISY Register
  [1:0] DAISY — Selecting Pads Involved in Daisy Chain.
    0=GPIO_EMC_13_ALT3 (Selecting Pad: GPIO_EMC_13 for Mode: ALT3); 1=GPIO_AD_B1_05_ALT3 (Selecting Pad: GPIO_AD_B1_05 for Mode: ALT3); 2=GPIO_EMC_21_ALT3 (Selecting Pad: GPIO_EMC_21 for Mode: ALT3)
0x43C SAI1_RX_DATA1_SELECT_INPUT — SAI1_RX_DATA1_SELECT_INPUT DAISY Register
  [0] DAISY — Selecting Pads Involved in Daisy Chain.
    0=GPIO_AD_B1_09_ALT3 (Selecting Pad: GPIO_AD_B1_09 for Mode: ALT3); 1=GPIO_EMC_22_ALT3 (Selecting Pad: GPIO_EMC_22 for Mode: ALT3)
0x440 SAI1_RX_DATA2_SELECT_INPUT — SAI1_RX_DATA2_SELECT_INPUT DAISY Register
  [0] DAISY — Selecting Pads Involved in Daisy Chain.
    0=GPIO_AD_B1_08_ALT3 (Selecting Pad: GPIO_AD_B1_08 for Mode: ALT3); 1=GPIO_EMC_23_ALT3 (Selecting Pad: GPIO_EMC_23 for Mode: ALT3)
0x444 SAI1_RX_DATA3_SELECT_INPUT — SAI1_RX_DATA3_SELECT_INPUT DAISY Register
  [0] DAISY — Selecting Pads Involved in Daisy Chain.
    0=GPIO_AD_B1_07_ALT3 (Selecting Pad: GPIO_AD_B1_07 for Mode: ALT3); 1=GPIO_EMC_24_ALT3 (Selecting Pad: GPIO_EMC_24 for Mode: ALT3)
0x448 SAI1_RX_SYNC_SELECT_INPUT — SAI1_RX_SYNC_SELECT_INPUT DAISY Register
  [1:0] DAISY — Selecting Pads Involved in Daisy Chain.
    0=GPIO_AD_B1_04_ALT3 (Selecting Pad: GPIO_AD_B1_04 for Mode: ALT3); 1=GPIO_EMC_15_ALT3 (Selecting Pad: GPIO_EMC_15 for Mode: ALT3); 2=GPIO_EMC_18_ALT3 (Selecting Pad: GPIO_EMC_18 for Mode: ALT3)
0x44C SAI1_TX_BCLK_SELECT_INPUT — SAI1_TX_BCLK_SELECT_INPUT DAISY Register
  [1:0] DAISY — Selecting Pads Involved in Daisy Chain.
    0=GPIO_EMC_11_ALT3 (Selecting Pad: GPIO_EMC_11 for Mode: ALT3); 1=GPIO_AD_B1_01_ALT3 (Selecting Pad: GPIO_AD_B1_01 for Mode: ALT3); 2=GPIO_EMC_26_ALT3 (Selecting Pad: GPIO_EMC_26 for Mode: ALT3)
0x450 SAI1_TX_SYNC_SELECT_INPUT — SAI1_TX_SYNC_SELECT_INPUT DAISY Register
  [1:0] DAISY — Selecting Pads Involved in Daisy Chain.
    0=GPIO_EMC_10_ALT3 (Selecting Pad: GPIO_EMC_10 for Mode: ALT3); 1=GPIO_AD_B1_02_ALT3 (Selecting Pad: GPIO_AD_B1_02 for Mode: ALT3); 2=GPIO_EMC_27_ALT3 (Selecting Pad: GPIO_EMC_27 for Mode: ALT3)
0x454 SAI2_MCLK_SELECT_INPUT — SAI2_MCLK_SELECT_INPUT DAISY Register
  [0] DAISY — Selecting Pads Involved in Daisy Chain.
    0=GPIO_SD_B0_00_ALT3 (Selecting Pad: GPIO_SD_B0_00 for Mode: ALT3); 1=GPIO_EMC_16_ALT3 (Selecting Pad: GPIO_EMC_16 for Mode: ALT3)
0x458 SAI2_RX_BCLK_SELECT_INPUT — SAI2_RX_BCLK_SELECT_INPUT DAISY Register
  [0] DAISY — Selecting Pads Involved in Daisy Chain.
    0=GPIO_SD_B0_02_ALT3 (Selecting Pad: GPIO_SD_B0_02 for Mode: ALT3); 1=GPIO_EMC_09_ALT3 (Selecting Pad: GPIO_EMC_09 for Mode: ALT3)
0x45C SAI2_RX_DATA0_SELECT_INPUT — SAI2_RX_DATA0_SELECT_INPUT DAISY Register
  [0] DAISY — Selecting Pads Involved in Daisy Chain.
    0=GPIO_SD_B0_03_ALT3 (Selecting Pad: GPIO_SD_B0_03 for Mode: ALT3); 1=GPIO_EMC_08_ALT3 (Selecting Pad: GPIO_EMC_08 for Mode: ALT3)
0x460 SAI2_RX_SYNC_SELECT_INPUT — SAI2_RX_SYNC_SELECT_INPUT DAISY Register
  [0] DAISY — Selecting Pads Involved in Daisy Chain.
    0=GPIO_SD_B0_01_ALT3 (Selecting Pad: GPIO_SD_B0_01 for Mode: ALT3); 1=GPIO_EMC_07_ALT3 (Selecting Pad: GPIO_EMC_07 for Mode: ALT3)
0x464 SAI2_TX_BCLK_SELECT_INPUT — SAI2_TX_BCLK_SELECT_INPUT DAISY Register
  [0] DAISY — Selecting Pads Involved in Daisy Chain.
    0=GPIO_SD_B0_05_ALT3 (Selecting Pad: GPIO_SD_B0_05 for Mode: ALT3); 1=GPIO_EMC_04_ALT3 (Selecting Pad: GPIO_EMC_04 for Mode: ALT3)
0x468 SAI2_TX_SYNC_SELECT_INPUT — SAI2_TX_SYNC_SELECT_INPUT DAISY Register
  [0] DAISY — Selecting Pads Involved in Daisy Chain.
    0=GPIO_SD_B0_06_ALT3 (Selecting Pad: GPIO_SD_B0_06 for Mode: ALT3); 1=GPIO_EMC_05_ALT3 (Selecting Pad: GPIO_EMC_05 for Mode: ALT3)
0x46C SAI3_MCLK_SELECT_INPUT — SAI3_MCLK_SELECT_INPUT DAISY Register
  [1:0] DAISY — Selecting Pads Involved in Daisy Chain.
    0=GPIO_SD_B1_05_ALT3 (Selecting Pad: GPIO_SD_B1_05 for Mode: ALT3); 1=GPIO_EMC_17_ALT3 (Selecting Pad: GPIO_EMC_17 for Mode: ALT3); 2=GPIO_EMC_28_ALT3 (Selecting Pad: GPIO_EMC_28 for Mode: ALT3)
0x470 SAI3_RX_BCLK_SELECT_INPUT — SAI3_RX_BCLK_SELECT_INPUT DAISY Register
  [0] DAISY — Selecting Pads Involved in Daisy Chain.
    0=GPIO_SD_B1_09_ALT3 (Selecting Pad: GPIO_SD_B1_09 for Mode: ALT3); 1=GPIO_EMC_29_ALT3 (Selecting Pad: GPIO_EMC_29 for Mode: ALT3)
0x474 SAI3_RX_DATA0_SELECT_INPUT — SAI3_RX_DATA0_SELECT_INPUT DAISY Register
  [0] DAISY — Selecting Pads Involved in Daisy Chain.
    0=GPIO_SD_B1_11_ALT3 (Selecting Pad: GPIO_SD_B1_11 for Mode: ALT3); 1=GPIO_EMC_31_ALT3 (Selecting Pad: GPIO_EMC_31 for Mode: ALT3)
0x478 SAI3_RX_SYNC_SELECT_INPUT — SAI3_RX_SYNC_SELECT_INPUT DAISY Register
  [0] DAISY — Selecting Pads Involved in Daisy Chain.
    0=GPIO_SD_B1_10_ALT3 (Selecting Pad: GPIO_SD_B1_10 for Mode: ALT3); 1=GPIO_EMC_30_ALT3 (Selecting Pad: GPIO_EMC_30 for Mode: ALT3)
0x47C SAI3_TX_BCLK_SELECT_INPUT — SAI3_TX_BCLK_SELECT_INPUT DAISY Register
  [0] DAISY — Selecting Pads Involved in Daisy Chain.
    0=GPIO_SD_B1_06_ALT3 (Selecting Pad: GPIO_SD_B1_06 for Mode: ALT3); 1=GPIO_EMC_33_ALT3 (Selecting Pad: GPIO_EMC_33 for Mode: ALT3)
0x480 SAI3_TX_SYNC_SELECT_INPUT — SAI3_TX_SYNC_SELECT_INPUT DAISY Register
  [0] DAISY — Selecting Pads Involved in Daisy Chain.
    0=GPIO_SD_B1_07_ALT3 (Selecting Pad: GPIO_SD_B1_07 for Mode: ALT3); 1=GPIO_EMC_34_ALT3 (Selecting Pad: GPIO_EMC_34 for Mode: ALT3)
0x484 SEMC_READY_SELECT_INPUT — SEMC_READY_SELECT_INPUT DAISY Register
  [0] DAISY — Selecting Pads Involved in Daisy Chain.
    0=GPIO_AD_B1_00_ALT0 (Selecting Pad: GPIO_AD_B1_00 for Mode: ALT0); 1=GPIO_EMC_41_ALT0 (Selecting Pad: GPIO_EMC_41 for Mode: ALT0)
0x488 SPDIF_IN_SELECT_INPUT — SPDIF_IN_SELECT_INPUT DAISY Register
  [0] DAISY — Selecting Pads Involved in Daisy Chain.
    0=GPIO_EMC_05_ALT2 (Selecting Pad: GPIO_EMC_05 for Mode: ALT2); 1=GPIO_EMC_41_ALT2 (Selecting Pad: GPIO_EMC_41 for Mode: ALT2)
0x48C USB_OTG_OC_SELECT_INPUT — USB_OTG_OC_SELECT_INPUT DAISY Register
  [1:0] DAISY — Selecting Pads Involved in Daisy Chain.
    0=GPIO_AD_B0_03_ALT6 (Selecting Pad: GPIO_AD_B0_03 for Mode: ALT6); 1=GPIO_AD_B1_12_ALT0 (Selecting Pad: GPIO_AD_B1_12 for Mode: ALT0); 2=GPIO_EMC_39_ALT3 (Selecting Pad: GPIO_EMC_39 for Mode: ALT3)
0x490 USDHC1_CD_B_SELECT_INPUT — USDHC1_CD_B_SELECT_INPUT DAISY Register
  [1:0] DAISY — Selecting Pads Involved in Daisy Chain.
    0=GPIO_SD_B0_06_ALT0 (Selecting Pad: GPIO_SD_B0_06 for Mode: ALT0); 1=GPIO_AD_B0_05_ALT2 (Selecting Pad: GPIO_AD_B0_05 for Mode: ALT2); 2=GPIO_AD_B1_10_ALT3 (Selecting Pad: GPIO_AD_B1_10 for Mode: ALT3); 3=GPIO_EMC_38_ALT7 (Selecting Pad: GPIO_EMC_38 for Mode: ALT7)
0x494 USDHC1_WP_SELECT_INPUT — USDHC1_WP_SELECT_INPUT DAISY Register
  [2:0] DAISY — Selecting Pads Involved in Daisy Chain.
    0=GPIO_AD_B0_03_ALT4 (Selecting Pad: GPIO_AD_B0_03 for Mode: ALT4); 1=GPIO_AD_B0_04_ALT2 (Selecting Pad: GPIO_AD_B0_04 for Mode: ALT2); 2=GPIO_AD_B1_05_ALT0 (Selecting Pad: GPIO_AD_B1_05 for Mode: ALT0); 3=GPIO_AD_B1_11_ALT3 (Selecting Pad: GPIO_AD_B1_11 for Mode: ALT3); 4=GPIO_EMC_36_ALT7 (Selecting Pad: GPIO_EMC_36 for Mode: ALT7)
0x498 USDHC2_CD_B_SELECT_INPUT — USDHC2_CD_B_SELECT_INPUT DAISY Register
  [1:0] DAISY — Selecting Pads Involved in Daisy Chain.
    0=GPIO_SD_B1_06_ALT0 (Selecting Pad: GPIO_SD_B1_06 for Mode: ALT0); 1=GPIO_AD_B0_03_ALT1 (Selecting Pad: GPIO_AD_B0_03 for Mode: ALT1); 2=GPIO_AD_B1_12_ALT3 (Selecting Pad: GPIO_AD_B1_12 for Mode: ALT3)
0x49C USDHC2_WP_SELECT_INPUT — USDHC2_WP_SELECT_INPUT DAISY Register
  [0] DAISY — Selecting Pads Involved in Daisy Chain.
    0=GPIO_AD_B1_13_ALT3 (Selecting Pad: GPIO_AD_B1_13 for Mode: ALT3); 1=GPIO_EMC_35_ALT3 (Selecting Pad: GPIO_EMC_35 for Mode: ALT3)
0x4A0 XBAR1_IN14_SELECT_INPUT — XBAR1_IN14_SELECT_INPUT DAISY Register
  [0] DAISY — Selecting Pads Involved in Daisy Chain.
    0=GPIO_SD_B0_00_ALT7 (Selecting Pad: GPIO_SD_B0_00 for Mode: ALT7); 1=GPIO_EMC_14_ALT1 (Selecting Pad: GPIO_EMC_14 for Mode: ALT1)
0x4A4 XBAR1_IN15_SELECT_INPUT — XBAR1_IN15_SELECT_INPUT DAISY Register
  [0] DAISY — Selecting Pads Involved in Daisy Chain.
    0=GPIO_SD_B0_01_ALT7 (Selecting Pad: GPIO_SD_B0_01 for Mode: ALT7); 1=GPIO_EMC_15_ALT1 (Selecting Pad: GPIO_EMC_15 for Mode: ALT1)
0x4A8 XBAR1_IN16_SELECT_INPUT — XBAR1_IN16_SELECT_INPUT DAISY Register
  [0] DAISY — Selecting Pads Involved in Daisy Chain.
    0=GPIO_SD_B0_02_ALT7 (Selecting Pad: GPIO_SD_B0_02 for Mode: ALT7); 1=GPIO_EMC_18_ALT1 (Selecting Pad: GPIO_EMC_18 for Mode: ALT1)
0x4AC XBAR1_IN17_SELECT_INPUT — XBAR1_IN17_SELECT_INPUT DAISY Register
  [0] DAISY — Selecting Pads Involved in Daisy Chain.
    0=GPIO_SD_B0_06_ALT6 (Selecting Pad: GPIO_SD_B0_06 for Mode: ALT6); 1=GPIO_EMC_19_ALT1 (Selecting Pad: GPIO_EMC_19 for Mode: ALT1)
0x4B0 XBAR1_IN10_SELECT_INPUT — XBAR1_IN10_SELECT_INPUT DAISY Register
  [0] DAISY — Selecting Pads Involved in Daisy Chain.
    0=GPIO_EMC_10_ALT1 (Selecting Pad: GPIO_EMC_10 for Mode: ALT1); 1=GPIO_SD_B1_00_ALT3 (Selecting Pad: GPIO_SD_B1_00 for Mode: ALT3)
0x4B4 XBAR1_IN12_SELECT_INPUT — XBAR1_IN12_SELECT_INPUT DAISY Register
  [0] DAISY — Selecting Pads Involved in Daisy Chain.
    0=GPIO_EMC_12_ALT1 (Selecting Pad: GPIO_EMC_12 for Mode: ALT1); 1=GPIO_AD_B1_08_ALT7 (Selecting Pad: GPIO_AD_B1_08 for Mode: ALT7)
0x4B8 XBAR1_IN13_SELECT_INPUT — XBAR1_IN13_SELECT_INPUT DAISY Register
  [0] DAISY — Selecting Pads Involved in Daisy Chain.
    0=GPIO_EMC_13_ALT1 (Selecting Pad: GPIO_EMC_13 for Mode: ALT1); 1=GPIO_AD_B1_09_ALT7 (Selecting Pad: GPIO_AD_B1_09 for Mode: ALT7)
0x4BC XBAR1_IN18_SELECT_INPUT — XBAR1_IN18_SELECT_INPUT DAISY Register
  [0] DAISY — Selecting Pads Involved in Daisy Chain.
    0=GPIO_EMC_28_ALT2 (Selecting Pad: GPIO_EMC_28 for Mode: ALT2); 1=GPIO_EMC_40_ALT1 (Selecting Pad: GPIO_EMC_40 for Mode: ALT1)
0x4C0 XBAR1_IN19_SELECT_INPUT — XBAR1_IN19_SELECT_INPUT DAISY Register
  [0] DAISY — Selecting Pads Involved in Daisy Chain.
    0=GPIO_EMC_29_ALT2 (Selecting Pad: GPIO_EMC_29 for Mode: ALT2); 1=GPIO_EMC_41_ALT1 (Selecting Pad: GPIO_EMC_41 for Mode: ALT1)
